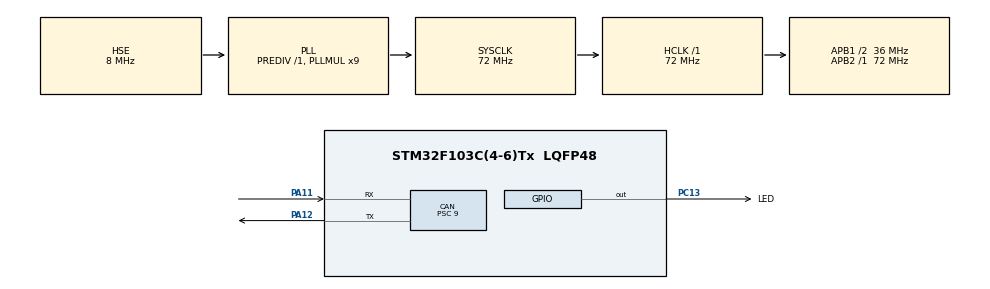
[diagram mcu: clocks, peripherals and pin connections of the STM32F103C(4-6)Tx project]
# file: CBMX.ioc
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CAN.BS1=CAN_BS1_3TQ
CAN.BS2=CAN_BS2_4TQ
CAN.CalculateTimeBit=2000
CAN.CalculateTimeQuantum=250.0
CAN.Prescaler=9
FREERTOS.Tasks01=defaultTask,0,128,StartDefaultTask,Default,NULL,Dynamic,NULL,NULL;LEDTask,-2,128,StartTask02,Default,NULL,Dynamic,NULL,NULL;CANIFRXTask,-1,128,StartTask03,Default,NULL,Dynamic,NULL,NULL;CANTPMF,-2,128,StartTask04,Default,NULL,Dynamic,NULL,NULL
FREERTOS.configTOTAL_HEAP_SIZE=5000
FREERTOS.configUSE_COUNTING_SEMAPHORES=1
FREERTOS.configUSE_RECURSIVE_MUTEXES=1
FREERTOS.configUSE_TIMERS=1
FREERTOS.configUSE_TRACE_FACILITY=1
Mcu.Family=STM32F1
Mcu.Name=STM32F103C(4-6)Tx
Mcu.Package=LQFP48
NVIC.CAN1_RX1_IRQn=true\:7\:0\:true\:false\:true\:true\:true\:true\:true
NVIC.PriorityGroup=NVIC_PRIORITYGROUP_4
NVIC.TIM1_UP_IRQn=true\:0\:0\:false\:false\:true\:false\:false\:true\:true
NVIC.TIM2_IRQn=true\:15\:0\:true\:false\:true\:true\:true\:true\:true
NVIC.TimeBase=TIM1_UP_IRQn
NVIC.TimeBaseIP=TIM1
NVIC.USB_LP_CAN1_RX0_IRQn=true\:6\:0\:true\:false\:true\:true\:true\:true\:true
PA11.Mode=Master
PA11.Signal=CAN_RX
PA12.Mode=Master
PA12.Signal=CAN_TX
PA13.Mode=Serial_Wire
PA13.Signal=SYS_JTMS-SWDIO
PA14.Mode=Serial_Wire
PA14.Signal=SYS_JTCK-SWCLK
PC13-TAMPER-RTC.GPIO_Label=LED
PC13-TAMPER-RTC.PinState=GPIO_PIN_SET
PC13-TAMPER-RTC.Signal=GPIO_Output
PD0-OSC_IN.Mode=HSE-External-Oscillator
PD0-OSC_IN.Signal=RCC_OSC_IN
PD1-OSC_OUT.Mode=HSE-External-Oscillator
PD1-OSC_OUT.Signal=RCC_OSC_OUT
ProjectManager.HeapSize=0x800
ProjectManager.StackSize=0x400
ProjectManager.TargetToolchain=Makefile
RCC.AHBFreq_Value=72000000
RCC.APB1CLKDivider=RCC_HCLK_DIV2
RCC.APB1Freq_Value=36000000
RCC.APB1TimFreq_Value=72000000
RCC.APB2Freq_Value=72000000
RCC.APB2TimFreq_Value=72000000
RCC.HCLKFreq_Value=72000000
RCC.PLLMUL=RCC_PLL_MUL9
RCC.PLLSourceVirtual=RCC_PLLSOURCE_HSE
RCC.SYSCLKFreq_VALUE=72000000
RCC.SYSCLKSource=RCC_SYSCLKSOURCE_PLLCLK
RCC.USBFreq_Value=72000000
TIM2.AutoReloadPreload=TIM_AUTORELOAD_PRELOAD_ENABLE
TIM2.Period=19999
TIM2.Prescaler=35999
VP_FREERTOS_VS_CMSIS_V1.Mode=CMSIS_V1
VP_SYS_VS_tim1.Mode=TIM1
VP_TIM2_VS_ClockSourceINT.Mode=Internal
board=custom

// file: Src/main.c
/* USER CODE BEGIN Header */
/**
  ******************************************************************************
  * @file           : main.c
  * @brief          : Main program body
  ******************************************************************************
  * @attention
  *
  * <h2><center>&copy; Copyright (c) 2024 STMicroelectronics.
  * All rights reserved.</center></h2>
  *
  * This software component is licensed by ST under BSD 3-Clause license,
  * the "License"; You may not use this file except in compliance with the
  * License. You may obtain a copy of the License at:
  *                        opensource.org/licenses/BSD-3-Clause
  *
  ******************************************************************************
  */
/* USER CODE END Header */

#include "main.h"
#include "cmsis_os.h"
#include "can.h"
#include "tim.h"
#include "gpio.h"
#include "canif.h"
#include "uds_diag.h"
#include "cantp.h"

void SystemClock_Config(void);
void MX_FREERTOS_Init(void);

/* USER CODE BEGIN 0 */
volatile uint8_t count;
extern volatile uint8_t global_session;
/* USER CODE END 0 */

int main(void)
{

  /* MCU Configuration--------------------------------------------------------*/

  /* Reset of all peripherals, Initializes the Flash interface and the Systick. */
  HAL_Init();

  /* Configure the system clock */
  SystemClock_Config();

  /* Initialize all configured peripherals */
  MX_GPIO_Init();
  MX_CAN_Init();
  MX_TIM2_Init();
  /* USER CODE BEGIN 2 */
  //CAN_Config();
  CAN_Init();
  CAN_SetTxPacket();
    /* USER CODE END 2 */

  /* Call init function for freertos objects (in freertos.c) */
  MX_FREERTOS_Init();

  /* Start scheduler */
  osKernelStart();

  /* We should never get here as control is now taken by the scheduler */

  /* Infinite loop */
  /* USER CODE BEGIN WHILE */
  PduInfoTRx pduInfo;
    pduInfo.Length = 8; // 设置数据长度为 8 字节
    // 填充发送数据
    for (uint32_t i = 0; i < pduInfo.Length; i++) {
        pduInfo.Data[i] = i;  // 示例数据为 0, 1, 2, ..., 7
    }

  while (1)
  {
    for(int i=0;i<20;i++){
      /* USER CODE END WHILE */
    // 调用 CanIf_Transmit 函数发送数据，使用 PDU ID 0
      //CanIf_Transmit(i, &pduInfo);
      //HAL_GPIO_TogglePin(LED_GPIO_Port,LED_Pin);
      //HAL_Delay(250);
    }

  }
  /* USER CODE END 3 */
}

void SystemClock_Config(void)
{
  RCC_OscInitTypeDef RCC_OscInitStruct = {0};
  RCC_ClkInitTypeDef RCC_ClkInitStruct = {0};

  /** Initializes the CPU, AHB and APB busses clocks
  */
  RCC_OscInitStruct.OscillatorType = RCC_OSCILLATORTYPE_HSE;
  RCC_OscInitStruct.HSEState = RCC_HSE_ON;
  RCC_OscInitStruct.HSEPredivValue = RCC_HSE_PREDIV_DIV1;
  RCC_OscInitStruct.HSIState = RCC_HSI_ON;
  RCC_OscInitStruct.PLL.PLLState = RCC_PLL_ON;
  RCC_OscInitStruct.PLL.PLLSource = RCC_PLLSOURCE_HSE;
  RCC_OscInitStruct.PLL.PLLMUL = RCC_PLL_MUL9;
  if (HAL_RCC_OscConfig(&RCC_OscInitStruct) != HAL_OK)
  {
    Error_Handler();
  }
  /** Initializes the CPU, AHB and APB busses clocks
  */
  RCC_ClkInitStruct.ClockType = RCC_CLOCKTYPE_HCLK|RCC_CLOCKTYPE_SYSCLK
                              |RCC_CLOCKTYPE_PCLK1|RCC_CLOCKTYPE_PCLK2;
  RCC_ClkInitStruct.SYSCLKSource = RCC_SYSCLKSOURCE_PLLCLK;
  RCC_ClkInitStruct.AHBCLKDivider = RCC_SYSCLK_DIV1;
  RCC_ClkInitStruct.APB1CLKDivider = RCC_HCLK_DIV2;
  RCC_ClkInitStruct.APB2CLKDivider = RCC_HCLK_DIV1;

  if (HAL_RCC_ClockConfig(&RCC_ClkInitStruct, FLASH_LATENCY_2) != HAL_OK)
  {
    Error_Handler();
  }
}

void HAL_TIM_PeriodElapsedCallback(TIM_HandleTypeDef *htim)
{
  if (htim->Instance == TIM1) {
    HAL_IncTick();
  }
  /* USER CODE BEGIN Callback 1 */
  if(htim->Instance == TIM2){
		if(count == 0){
			count++;
			return;
		}

		//		__HAL_TIM_CLEAR_FLAG(htim, TIM_FLAG_UPDATE);
		else if (global_session != DefaultSession)
		{
			global_session = DefaultSession;
			//			global_sec_flag = Un_Secure;
		}
		else
		{
			// do nothing
		}
		//		stop_timer();
		reset_timer();
	}
  /* USER CODE END Callback 1 */
}

void Error_Handler(void)
{
}

/************************ (C) COPYRIGHT STMicroelectronics *****END OF FILE****/

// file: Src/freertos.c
/* USER CODE BEGIN Header */
/**
  ******************************************************************************
  * File Name          : freertos.c
  * Description        : Code for freertos applications
  ******************************************************************************
  * @attention
  *
  * <h2><center>&copy; Copyright (c) 2024 STMicroelectronics.
  * All rights reserved.</center></h2>
  *
  * This software component is licensed by ST under Ultimate Liberty license
  * SLA0044, the "License"; You may not use this file except in compliance with
  * the License. You may obtain a copy of the License at:
  *                             www.st.com/SLA0044
  *
  ******************************************************************************
  */
/* USER CODE END Header */

#include "FreeRTOS.h"
#include "task.h"
#include "main.h"
#include "cmsis_os.h"
#include "cantp.h"

osThreadId defaultTaskHandle;
osThreadId LEDTaskHandle;
osThreadId CANIFRXTaskHandle;
//osThreadId CANTPMFHandle;

void StartDefaultTask(void const * argument);
void StartTask02(void const * argument);
void StartTask03(void const * argument);
//void StartTask04(void const * argument);

void MX_FREERTOS_Init(void); /* (MISRA C 2004 rule 8.1) */

void MX_FREERTOS_Init(void) {

  /* Create the thread(s) */
  /* definition and creation of defaultTask */
  osThreadDef(defaultTask, StartDefaultTask, osPriorityNormal, 0, 128);
  defaultTaskHandle = osThreadCreate(osThread(defaultTask), NULL);

  /* definition and creation of LEDTask */
  osThreadDef(LEDTask, StartTask02, osPriorityLow, 0, 128);
  LEDTaskHandle = osThreadCreate(osThread(LEDTask), NULL);

  /* definition and creation of CANIFRXTask */
  osThreadDef(CANIFRXTask, StartTask03, osPriorityBelowNormal, 0, 128);
  CANIFRXTaskHandle = osThreadCreate(osThread(CANIFRXTask), NULL);

  /* definition and creation of CANTPMF */
  // osThreadDef(CANTPMF, StartTask04, osPriorityLow, 0, 128);
  // CANTPMFHandle = osThreadCreate(osThread(CANTPMF), NULL);

}

void StartDefaultTask(void const * argument)
{

  for(;;)
  {
    osDelay(1);
  }
}

void StartTask02(void const * argument)
{
  /* USER CODE BEGIN StartTask02 */
  /* Infinite loop */
  for(;;)
  {
    CanTp_MainFunction();
    //HAL_GPIO_TogglePin(LED_GPIO_Port,LED_Pin);
    osDelay(1);
  }
  /* USER CODE END StartTask02 */
}

void StartTask03(void const * argument)
{
  /* USER CODE BEGIN StartTask03 */
  /* Infinite loop */
  for(;;)
  {
    CanIf_Receive();
    osDelay(1);
  }
  /* USER CODE END StartTask03 */
}

// void StartTask04(void const * argument)
// {
//   /* USER CODE BEGIN StartTask04 */
//   /* Infinite loop */
//   for(;;)
//   {
//
//     osDelay(1);
//   }
//   /* USER CODE END StartTask04 */
// }

/************************ (C) COPYRIGHT STMicroelectronics *****END OF FILE****/
